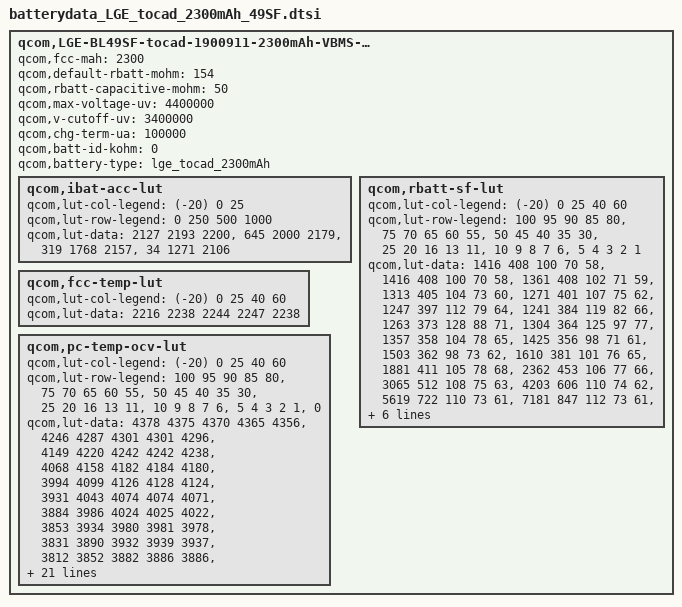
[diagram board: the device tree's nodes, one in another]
 qcom,LGE-BL49SF-tocad-1900911-2300mAh-VBMS-data {
	qcom,fcc-mah = <2300>;
	qcom,default-rbatt-mohm = <154>;
	qcom,rbatt-capacitive-mohm = <50>;
	qcom,max-voltage-uv = <4400000>;
	qcom,v-cutoff-uv = <3400000>;
	qcom,chg-term-ua = <100000>;
	qcom,batt-id-kohm = <0>;
	qcom,battery-type = "lge_tocad_2300mAh";

	qcom,ibat-acc-lut {
		qcom,lut-col-legend = <(-20) 0 25>;
		qcom,lut-row-legend = <0 250 500 1000>;
		qcom,lut-data = <2127 2193 2200>,
				<645 2000 2179>,
				<319 1768 2157>,
				<34 1271 2106>;
	};

	qcom,rbatt-sf-lut {
		qcom,lut-col-legend = <(-20) 0 25 40 60>;
		qcom,lut-row-legend = <100 95 90 85 80>,
				<75 70 65 60 55>,
				<50 45 40 35 30>,
				<25 20 16 13 11>,
				<10 9 8 7 6>,
				<5 4 3 2 1>;
		qcom,lut-data = <1416 408 100 70 58>,
				<1416 408 100 70 58>,
				<1361 408 102 71 59>,
				<1313 405 104 73 60>,
				<1271 401 107 75 62>,
				<1247 397 112 79 64>,
				<1241 384 119 82 66>,
				<1263 373 128 88 71>,
				<1304 364 125 97 77>,
				<1357 358 104 78 65>,
				<1425 356 98 71 61>,
				<1503 362 98 73 62>,
				<1610 381 101 76 65>,
				<1881 411 105 78 68>,
				<2362 453 106 77 66>,
				<3065 512 108 75 63>,
				<4203 606 110 74 62>,
				<5619 722 110 73 61>,
				<7181 847 112 73 61>,
				<9197 957 118 75 64>,
				<10260 1016 122 78 66>,
				<11666 1077 127 81 68>,
				<13236 1108 131 82 69>,
				<15090 1158 138 86 70>,
				<17923 1269 145 86 67>,
				<22497 1504 146 82 66>,
				<29434 2036 147 85 69>,
				<41290 3090 164 92 78>,
				<64844 5446 201 109 95>,
				<116138 10892 355 184 190>;
	};

	qcom,fcc-temp-lut {
		qcom,lut-col-legend = <(-20) 0 25 40 60>;
		qcom,lut-data = <2216 2238 2244 2247 2238>;
	};

	qcom,pc-temp-ocv-lut {
		qcom,lut-col-legend = <(-20) 0 25 40 60>;
		qcom,lut-row-legend = <100 95 90 85 80>,
				<75 70 65 60 55>,
				<50 45 40 35 30>,
				<25 20 16 13 11>,
				<10 9 8 7 6>,
				<5 4 3 2 1>,
				<0>;
		qcom,lut-data = <4378 4375 4370 4365 4356>,
				<4246 4287 4301 4301 4296>,
				<4149 4220 4242 4242 4238>,
				<4068 4158 4182 4184 4180>,
				<3994 4099 4126 4128 4124>,
				<3931 4043 4074 4074 4071>,
				<3884 3986 4024 4025 4022>,
				<3853 3934 3980 3981 3978>,
				<3831 3890 3932 3939 3937>,
				<3812 3852 3882 3886 3886>,
				<3794 3820 3846 3850 3850>,
				<3776 3798 3821 3825 3825>,
				<3756 3782 3801 3804 3804>,
				<3736 3766 3784 3787 3787>,
				<3714 3750 3770 3771 3764>,
				<3690 3730 3756 3752 3740>,
				<3661 3708 3734 3730 3716>,
				<3632 3691 3706 3702 3688>,
				<3604 3678 3685 3682 3669>,
				<3579 3668 3678 3677 3666>,
				<3566 3662 3676 3676 3665>,
				<3550 3654 3674 3674 3664>,
				<3531 3646 3672 3672 3662>,
				<3512 3636 3668 3669 3655>,
				<3489 3619 3658 3657 3633>,
				<3456 3596 3628 3622 3590>,
				<3412 3558 3577 3568 3532>,
				<3350 3502 3507 3496 3456>,
				<3261 3419 3411 3398 3350>,
				<3149 3284 3260 3234 3193>,
				<3000 3000 3000 3000 3000>;
	};
};
